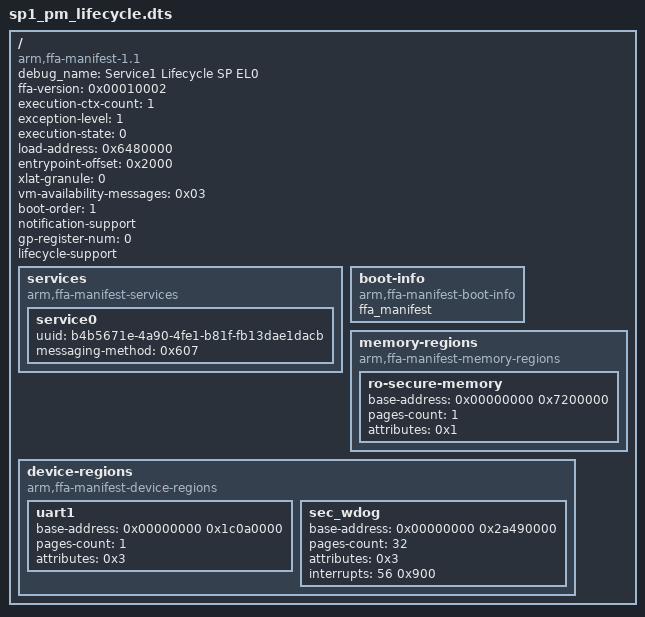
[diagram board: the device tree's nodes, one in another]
/*
 * Copyright 2025 The Hafnium Authors.
 *
 * Use of this source code is governed by a BSD-style
 * license that can be found in the LICENSE file or at
 * https://opensource.org/licenses/BSD-3-Clause.
 */

/dts-v1/;

/ {
	compatible = "arm,ffa-manifest-1.1";
	debug_name = "Service1 Lifecycle SP EL0";

	/* Properties */
	ffa-version = <0x00010002>; /* 31:16 - Major, 15:0 - Minor */
	execution-ctx-count = <1>;
	exception-level = <1>; /* S-EL0 */
	execution-state = <0>; /* AARCH64 */
	load-address = <0x6480000>;
	entrypoint-offset = <0x2000>;
	xlat-granule = <0>; /* 4KiB */
	vm-availability-messages = <0x03>; /* Supports VM created and VM destroyed messages. */
	boot-order = <1>;
	notification-support; /* Receipt of notifications. */
	gp-register-num = <0>;
	lifecycle-support;

	services {
		compatible = "arm,ffa-manifest-services";

		service0 {
			uuid = "b4b5671e-4a90-4fe1-b81f-fb13dae1dacb";
			messaging-method = <0x607>; /* Supports direct (both APIs) and indirect requests. */
		};
	};

	/* Boot Info */
	boot-info {
		compatible = "arm,ffa-manifest-boot-info";
		ffa_manifest;
	};

	memory-regions {
		compatible = "arm,ffa-manifest-memory-regions";

		ro-secure-memory {
			base-address = <0x00000000 0x7200000>;
			pages-count = <1>;
			attributes = <0x1>; /* read-only */
		};
	};

	device-regions {
		compatible = "arm,ffa-manifest-device-regions";

		uart1 {
			base-address = <0x00000000 0x1c0a0000>;
			pages-count = <1>;
			attributes = <0x3>; /* read-write */
		};

		sec_wdog {
			/* SP805 Trusted Watchdog Module */
			base-address = <0x00000000 0x2a490000>;
			pages-count = <32>; /* Two 64KB pages */
			attributes = <0x3>; /* read-write */
			interrupts = <56 0x900>;
		};
	};
};
